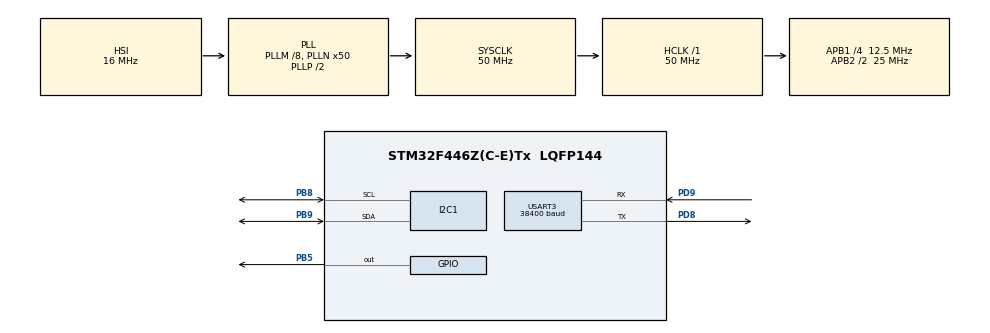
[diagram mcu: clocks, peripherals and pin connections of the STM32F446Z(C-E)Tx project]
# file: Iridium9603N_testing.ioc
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Mcu.Family=STM32F4
Mcu.Name=STM32F446Z(C-E)Tx
Mcu.Package=LQFP144
NVIC.PriorityGroup=NVIC_PRIORITYGROUP_4
NVIC.TIM1_UP_TIM10_IRQn=true\:15\:0\:false\:false\:true\:false\:true
NVIC.TimeBase=TIM1_UP_TIM10_IRQn
NVIC.TimeBaseIP=TIM1
PB5.Signal=GPIO_Output
PB8.Mode=I2C
PB8.Signal=I2C1_SCL
PB9.Mode=I2C
PB9.Signal=I2C1_SDA
PD8.Mode=Asynchronous
PD8.Signal=USART3_TX
PD9.Mode=Asynchronous
PD9.Signal=USART3_RX
ProjectManager.HeapSize=0x200
ProjectManager.StackSize=0x400
ProjectManager.TargetToolchain=STM32CubeIDE
RCC.48MHZClocksFreq_Value=24000000
RCC.AHBFreq_Value=50000000
RCC.APB1CLKDivider=RCC_HCLK_DIV4
RCC.APB1Freq_Value=12500000
RCC.APB1TimFreq_Value=25000000
RCC.APB2CLKDivider=RCC_HCLK_DIV2
RCC.APB2Freq_Value=25000000
RCC.APB2TimFreq_Value=50000000
RCC.CortexFreq_Value=50000000
RCC.HCLKFreq_Value=50000000
RCC.HSE_VALUE=8000000
RCC.HSI_VALUE=16000000
RCC.PLLM=8
RCC.PLLMUL=RCC_PLL_MUL9
RCC.PLLN=50
RCC.PLLQ=7
RCC.PRESCALERUSB=RCC_USBCLKSOURCE_PLL_DIV1_5
RCC.SYSCLKFreq_VALUE=50000000
RCC.SYSCLKSource=RCC_SYSCLKSOURCE_PLLCLK
RCC.SYSCLKSourceVirtual=RCC_SYSCLKSOURCE_PLLCLK
RCC.USBFreq_Value=14285714.285714285
RCC.VCOOutputFreq_Value=100000000
USART3.BaudRate=38400
USART3.VirtualMode=VM_ASYNC
VP_SYS_VS_tim1.Mode=TIM1
board=NUCLEO-F446ZE

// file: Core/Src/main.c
/* USER CODE BEGIN Header */
/**
  ******************************************************************************
  * @file           : main.c
  * @brief          : Main program body
  ******************************************************************************
  * @attention
  *
  * <h2><center>&copy; Copyright (c) 2021 STMicroelectronics.
  * All rights reserved.</center></h2>
  *
  * This software component is licensed by ST under BSD 3-Clause license,
  * the "License"; You may not use this file except in compliance with the
  * License. You may obtain a copy of the License at:
  *                        opensource.org/licenses/BSD-3-Clause
  *
  ******************************************************************************
  */
/* USER CODE END Header */
#include "main.h"

/* USER CODE BEGIN Includes */

#include <IridiumSBD_Static_API.h>

/* USER CODE END Includes */

/* USER CODE BEGIN PD */

/*
 * Bug concerning HAL_transmit:invalid conversion from 'const char*' to 'uint8_t*' {aka 'unsigned char*'} [-fpermissive]
 * https://community.st.com/s/question/0D53W000005qNDr/signature-issue-in-hal-function-haluarttransmit-how-to-file-a-bugchange-request
 */
#define DIAGNOSTICS false

/* USER CODE END PD */

I2C_HandleTypeDef hi2c1;

UART_HandleTypeDef huart3;

void SystemClock_Config(void);
static void MX_GPIO_Init(void);
static void MX_USART3_UART_Init(void);
static void MX_I2C1_Init(void);

int main(void)
{

  /* MCU Configuration--------------------------------------------------------*/

  /* Reset of all peripherals, Initializes the Flash interface and the Systick. */
  HAL_Init();

  /* Configure the system clock */
  SystemClock_Config();

  /* Initialize all configured peripherals */
  MX_GPIO_Init();
  MX_USART3_UART_Init();
  MX_I2C1_Init();
  /* USER CODE BEGIN 2 */

  MRT_Static_Iridium_Setup(huart3);
  MRT_Static_Iridium_getIMEI();
  /*
  while(!MRT_Static_Iridium_getTime()){
	  HAL_Delay(1000);
  }

  while(!MRT_Static_Iridium_NetworkAvailability()){
	  HAL_Delay(100);
  }
  */

  //MRT_Static_Iridium_sendMessage("Rocket goes brrrrr");
  MRT_Static_Iridium_Shutdown();

  /* USER CODE END 2 */

  /* Infinite loop */
  while (1)
  {

  }
}

void SystemClock_Config(void)
{
  RCC_OscInitTypeDef RCC_OscInitStruct = {0};
  RCC_ClkInitTypeDef RCC_ClkInitStruct = {0};

  /** Configure the main internal regulator output voltage
  */
  __HAL_RCC_PWR_CLK_ENABLE();
  __HAL_PWR_VOLTAGESCALING_CONFIG(PWR_REGULATOR_VOLTAGE_SCALE3);
  /** Initializes the RCC Oscillators according to the specified parameters
  * in the RCC_OscInitTypeDef structure.
  */
  RCC_OscInitStruct.OscillatorType = RCC_OSCILLATORTYPE_HSI;
  RCC_OscInitStruct.HSIState = RCC_HSI_ON;
  RCC_OscInitStruct.HSICalibrationValue = RCC_HSICALIBRATION_DEFAULT;
  RCC_OscInitStruct.PLL.PLLState = RCC_PLL_ON;
  RCC_OscInitStruct.PLL.PLLSource = RCC_PLLSOURCE_HSI;
  RCC_OscInitStruct.PLL.PLLM = 8;
  RCC_OscInitStruct.PLL.PLLN = 50;
  RCC_OscInitStruct.PLL.PLLP = RCC_PLLP_DIV2;
  RCC_OscInitStruct.PLL.PLLQ = 7;
  RCC_OscInitStruct.PLL.PLLR = 2;
  if (HAL_RCC_OscConfig(&RCC_OscInitStruct) != HAL_OK)
  {
    Error_Handler();
  }
  /** Initializes the CPU, AHB and APB buses clocks
  */
  RCC_ClkInitStruct.ClockType = RCC_CLOCKTYPE_HCLK|RCC_CLOCKTYPE_SYSCLK
                              |RCC_CLOCKTYPE_PCLK1|RCC_CLOCKTYPE_PCLK2;
  RCC_ClkInitStruct.SYSCLKSource = RCC_SYSCLKSOURCE_PLLCLK;
  RCC_ClkInitStruct.AHBCLKDivider = RCC_SYSCLK_DIV1;
  RCC_ClkInitStruct.APB1CLKDivider = RCC_HCLK_DIV4;
  RCC_ClkInitStruct.APB2CLKDivider = RCC_HCLK_DIV2;

  if (HAL_RCC_ClockConfig(&RCC_ClkInitStruct, FLASH_LATENCY_1) != HAL_OK)
  {
    Error_Handler();
  }
}

static void MX_I2C1_Init(void)
{

  hi2c1.Instance = I2C1;
  hi2c1.Init.ClockSpeed = 100000;
  hi2c1.Init.DutyCycle = I2C_DUTYCYCLE_2;
  hi2c1.Init.OwnAddress1 = 0;
  hi2c1.Init.AddressingMode = I2C_ADDRESSINGMODE_7BIT;
  hi2c1.Init.DualAddressMode = I2C_DUALADDRESS_DISABLE;
  hi2c1.Init.OwnAddress2 = 0;
  hi2c1.Init.GeneralCallMode = I2C_GENERALCALL_DISABLE;
  hi2c1.Init.NoStretchMode = I2C_NOSTRETCH_DISABLE;
  if (HAL_I2C_Init(&hi2c1) != HAL_OK)
  {
    Error_Handler();
  }

}

static void MX_USART3_UART_Init(void)
{

  huart3.Instance = USART3;
  huart3.Init.BaudRate = 38400;
  huart3.Init.WordLength = UART_WORDLENGTH_8B;
  huart3.Init.StopBits = UART_STOPBITS_1;
  huart3.Init.Parity = UART_PARITY_NONE;
  huart3.Init.Mode = UART_MODE_TX_RX;
  huart3.Init.HwFlowCtl = UART_HWCONTROL_NONE;
  huart3.Init.OverSampling = UART_OVERSAMPLING_16;
  if (HAL_UART_Init(&huart3) != HAL_OK)
  {
    Error_Handler();
  }

}

static void MX_GPIO_Init(void)
{
  GPIO_InitTypeDef GPIO_InitStruct = {0};

  /* GPIO Ports Clock Enable */
  __HAL_RCC_GPIOD_CLK_ENABLE();
  __HAL_RCC_GPIOB_CLK_ENABLE();

  /*Configure GPIO pin Output Level */
  HAL_GPIO_WritePin(GPIOB, GPIO_PIN_5, GPIO_PIN_RESET);

  /*Configure GPIO pin : PB5 */
  GPIO_InitStruct.Pin = GPIO_PIN_5;
  GPIO_InitStruct.Mode = GPIO_MODE_OUTPUT_PP;
  GPIO_InitStruct.Pull = GPIO_NOPULL;
  GPIO_InitStruct.Speed = GPIO_SPEED_FREQ_LOW;
  HAL_GPIO_Init(GPIOB, &GPIO_InitStruct);

}

void HAL_TIM_PeriodElapsedCallback(TIM_HandleTypeDef *htim)
{
  if (htim->Instance == TIM1) {
    HAL_IncTick();
  }
}

void Error_Handler(void)
{
  __disable_irq();
  while (1)
  {
  }
}

/************************ (C) COPYRIGHT STMicroelectronics *****END OF FILE****/
